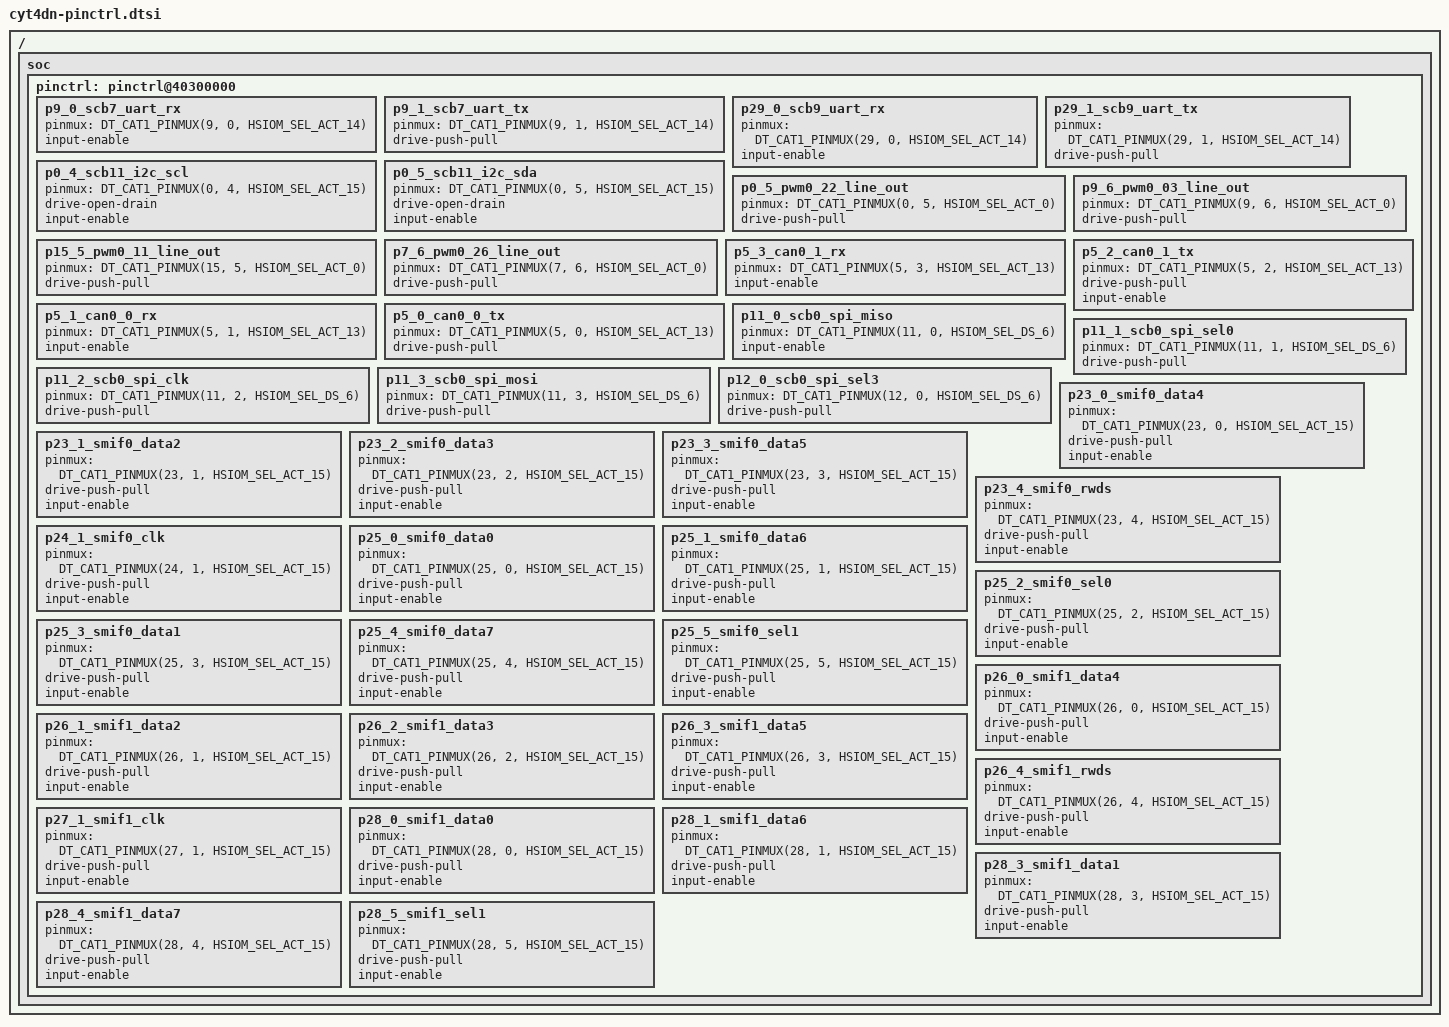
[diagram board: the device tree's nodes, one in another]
/*
 * Copyright (c) 2025 Linumiz GmbH
 *
 * SPDX-License-Identifier: Apache-2.0
 */

#include <zephyr/dt-bindings/gpio/gpio.h>
#include <zephyr/dt-bindings/pinctrl/ifx_cat1-pinctrl.h>
#include "cyt4dn.dtsi"

/ {
	soc {
		pinctrl: pinctrl@40300000 {
			/omit-if-no-ref/ p9_0_scb7_uart_rx: p9_0_scb7_uart_rx {
				pinmux = <DT_CAT1_PINMUX(9, 0, HSIOM_SEL_ACT_14)>;
				input-enable;
			};

			/omit-if-no-ref/ p9_1_scb7_uart_tx: p9_1_scb7_uart_tx {
				pinmux = <DT_CAT1_PINMUX(9, 1, HSIOM_SEL_ACT_14)>;
				drive-push-pull;
			};
			/omit-if-no-ref/ p29_0_scb9_uart_rx: p29_0_scb9_uart_rx {
				pinmux = <DT_CAT1_PINMUX(29, 0, HSIOM_SEL_ACT_14)>;
				input-enable;
			};

			/omit-if-no-ref/ p29_1_scb9_uart_tx: p29_1_scb9_uart_tx {
				pinmux = <DT_CAT1_PINMUX(29, 1, HSIOM_SEL_ACT_14)>;
				drive-push-pull;
			};

                       /omit-if-no-ref/ p0_4_scb11_i2c_scl: p0_4_scb11_i2c_scl {
                                pinmux = <DT_CAT1_PINMUX(0, 4, HSIOM_SEL_ACT_15)>;
                                drive-open-drain;
                                input-enable;
                        };

                        /omit-if-no-ref/ p0_5_scb11_i2c_sda: p0_5_scb11_i2c_sda {
                                pinmux = <DT_CAT1_PINMUX(0, 5, HSIOM_SEL_ACT_15)>;
                                drive-open-drain;
                                input-enable;
			};

                        /omit-if-no-ref/ p0_5_pwm0_22_line_out: p0_5_pwm0_22_line_out {
				pinmux = <DT_CAT1_PINMUX(0, 5, HSIOM_SEL_ACT_0)>;
				drive-push-pull;
                        };

			/omit-if-no-ref/ p9_6_pwm0_03_line_out:  p9_6_pwm0_03_line_out {
				pinmux = <DT_CAT1_PINMUX(9, 6, HSIOM_SEL_ACT_0)>;
				drive-push-pull;
			};

			/omit-if-no-ref/ p15_5_pwm0_11_line_out:  p15_5_pwm0_11_line_out {
				pinmux = <DT_CAT1_PINMUX(15, 5, HSIOM_SEL_ACT_0)>;
				drive-push-pull;
			};

			/omit-if-no-ref/ p7_6_pwm0_26_line_out:  p7_6_pwm0_26_line_out {
				pinmux = <DT_CAT1_PINMUX(7, 6, HSIOM_SEL_ACT_0)>;
				drive-push-pull;
			};

			/omit-if-no-ref/ p5_3_can0_1_rx: p5_3_can0_1_rx {
				pinmux = <DT_CAT1_PINMUX(5, 3, HSIOM_SEL_ACT_13)>;
				input-enable;
			};

			/omit-if-no-ref/ p5_2_can0_1_tx: p5_2_can0_1_tx {
				pinmux = <DT_CAT1_PINMUX(5, 2, HSIOM_SEL_ACT_13)>;
				drive-push-pull;
				input-enable;
			};

			/omit-if-no-ref/ p5_1_can0_0_rx: p5_1_can0_0_rx {
				pinmux = <DT_CAT1_PINMUX(5, 1, HSIOM_SEL_ACT_13)>;
				input-enable;
			};

			/omit-if-no-ref/ p5_0_can0_0_tx: p5_0_can0_0_tx {
				pinmux = <DT_CAT1_PINMUX(5, 0, HSIOM_SEL_ACT_13)>;
				drive-push-pull;
			};

			/omit-if-no-ref/ p11_0_scb0_spi_miso: p11_0_scb0_spi_miso {
				pinmux = <DT_CAT1_PINMUX(11, 0, HSIOM_SEL_DS_6)>;
				input-enable;
			};

			/omit-if-no-ref/ p11_1_scb0_spi_sel0: p11_1_scb0_spi_sel0 {
				pinmux = <DT_CAT1_PINMUX(11, 1, HSIOM_SEL_DS_6)>;
				drive-push-pull;
			};

			/omit-if-no-ref/ p11_2_scb0_spi_clk: p11_2_scb0_spi_clk {
				pinmux = <DT_CAT1_PINMUX(11, 2, HSIOM_SEL_DS_6)>;
				drive-push-pull;
			};

			/omit-if-no-ref/ p11_3_scb0_spi_mosi: p11_3_scb0_spi_mosi {
				pinmux = <DT_CAT1_PINMUX(11, 3, HSIOM_SEL_DS_6)>;
				drive-push-pull;
			};

			/omit-if-no-ref/ p12_0_scb0_spi_sel3: p12_0_scb0_spi_sel3 {
				pinmux = <DT_CAT1_PINMUX(12, 0, HSIOM_SEL_DS_6)>;
				drive-push-pull;
			};

			/* SMIF0 pins */
			/omit-if-no-ref/ p23_0_smif0_data4: p23_0_smif0_data4 {
				pinmux = <DT_CAT1_PINMUX(23, 0, HSIOM_SEL_ACT_15)>;
				drive-push-pull;
				input-enable;
			};

			/omit-if-no-ref/ p23_1_smif0_data2: p23_1_smif0_data2 {
				pinmux = <DT_CAT1_PINMUX(23, 1, HSIOM_SEL_ACT_15)>;
				drive-push-pull;
				input-enable;
			};

			/omit-if-no-ref/ p23_2_smif0_data3: p23_2_smif0_data3 {
				pinmux = <DT_CAT1_PINMUX(23, 2, HSIOM_SEL_ACT_15)>;
				drive-push-pull;
				input-enable;
			};

			/omit-if-no-ref/ p23_3_smif0_data5: p23_3_smif0_data5 {
				pinmux = <DT_CAT1_PINMUX(23, 3, HSIOM_SEL_ACT_15)>;
				drive-push-pull;
				input-enable;
			};

			/omit-if-no-ref/ p23_4_smif0_rwds: p23_4_smif0_rwds {
				pinmux = <DT_CAT1_PINMUX(23, 4, HSIOM_SEL_ACT_15)>;
				drive-push-pull;
				input-enable;
			};

			/omit-if-no-ref/ p24_1_smif0_clk: p24_1_smif0_clk {
				pinmux = <DT_CAT1_PINMUX(24, 1, HSIOM_SEL_ACT_15)>;
				drive-push-pull;
				input-enable;
			};

			/omit-if-no-ref/ p25_0_smif0_data0: p25_0_smif0_data0 {
				pinmux = <DT_CAT1_PINMUX(25, 0, HSIOM_SEL_ACT_15)>;
				drive-push-pull;
				input-enable;
			};

			/omit-if-no-ref/ p25_1_smif0_data6: p25_1_smif0_data6 {
				pinmux = <DT_CAT1_PINMUX(25, 1, HSIOM_SEL_ACT_15)>;
				drive-push-pull;
				input-enable;
			};

			/omit-if-no-ref/ p25_2_smif0_sel0: p25_2_smif0_sel0 {
				pinmux = <DT_CAT1_PINMUX(25, 2, HSIOM_SEL_ACT_15)>;
				drive-push-pull;
				input-enable;
			};

			/omit-if-no-ref/ p25_3_smif0_data1: p25_3_smif0_data1 {
				pinmux = <DT_CAT1_PINMUX(25, 3, HSIOM_SEL_ACT_15)>;
				drive-push-pull;
				input-enable;
			};

			/omit-if-no-ref/ p25_4_smif0_data7: p25_4_smif0_data7 {
				pinmux = <DT_CAT1_PINMUX(25, 4, HSIOM_SEL_ACT_15)>;
				drive-push-pull;
				input-enable;
			};

			/omit-if-no-ref/ p25_5_smif0_sel1: p25_5_smif0_sel1 {
				pinmux = <DT_CAT1_PINMUX(25, 5, HSIOM_SEL_ACT_15)>;
				drive-push-pull;
				input-enable;
			};

			/* SMIF1 pins */
			/omit-if-no-ref/ p26_0_smif1_data4: p26_0_smif1_data4 {
				pinmux = <DT_CAT1_PINMUX(26, 0, HSIOM_SEL_ACT_15)>;
				drive-push-pull;
				input-enable;
			};

			/omit-if-no-ref/ p26_1_smif1_data2: p26_1_smif1_data2 {
				pinmux = <DT_CAT1_PINMUX(26, 1, HSIOM_SEL_ACT_15)>;
				drive-push-pull;
				input-enable;
			};

			/omit-if-no-ref/ p26_2_smif1_data3: p26_2_smif1_data3 {
				pinmux = <DT_CAT1_PINMUX(26, 2, HSIOM_SEL_ACT_15)>;
				drive-push-pull;
				input-enable;
			};

			/omit-if-no-ref/ p26_3_smif1_data5: p26_3_smif1_data5 {
				pinmux = <DT_CAT1_PINMUX(26, 3, HSIOM_SEL_ACT_15)>;
				drive-push-pull;
				input-enable;
			};

			/omit-if-no-ref/ p26_4_smif1_rwds: p26_4_smif1_rwds {
				pinmux = <DT_CAT1_PINMUX(26, 4, HSIOM_SEL_ACT_15)>;
				drive-push-pull;
				input-enable;
			};

			/omit-if-no-ref/ p27_1_smif1_clk: p27_1_smif1_clk {
				pinmux = <DT_CAT1_PINMUX(27, 1, HSIOM_SEL_ACT_15)>;
				drive-push-pull;
				input-enable;
			};

			/omit-if-no-ref/ p28_0_smif1_data0: p28_0_smif1_data0 {
				pinmux = <DT_CAT1_PINMUX(28, 0, HSIOM_SEL_ACT_15)>;
				drive-push-pull;
				input-enable;
			};

			/omit-if-no-ref/ p28_1_smif1_data6: p28_1_smif1_data6 {
				pinmux = <DT_CAT1_PINMUX(28, 1, HSIOM_SEL_ACT_15)>;
				drive-push-pull;
				input-enable;
			};

			/omit-if-no-ref/ p28_3_smif1_data1: p28_3_smif1_data1 {
				pinmux = <DT_CAT1_PINMUX(28, 3, HSIOM_SEL_ACT_15)>;
				drive-push-pull;
				input-enable;
			};

			/omit-if-no-ref/ p28_4_smif1_data7: p28_4_smif1_data7 {
				pinmux = <DT_CAT1_PINMUX(28, 4, HSIOM_SEL_ACT_15)>;
				drive-push-pull;
				input-enable;
			};

			/omit-if-no-ref/ p28_5_smif1_sel1: p28_5_smif1_sel1 {
				pinmux = <DT_CAT1_PINMUX(28, 5, HSIOM_SEL_ACT_15)>;
				drive-push-pull;
				input-enable;
			};
		};
	};
};
